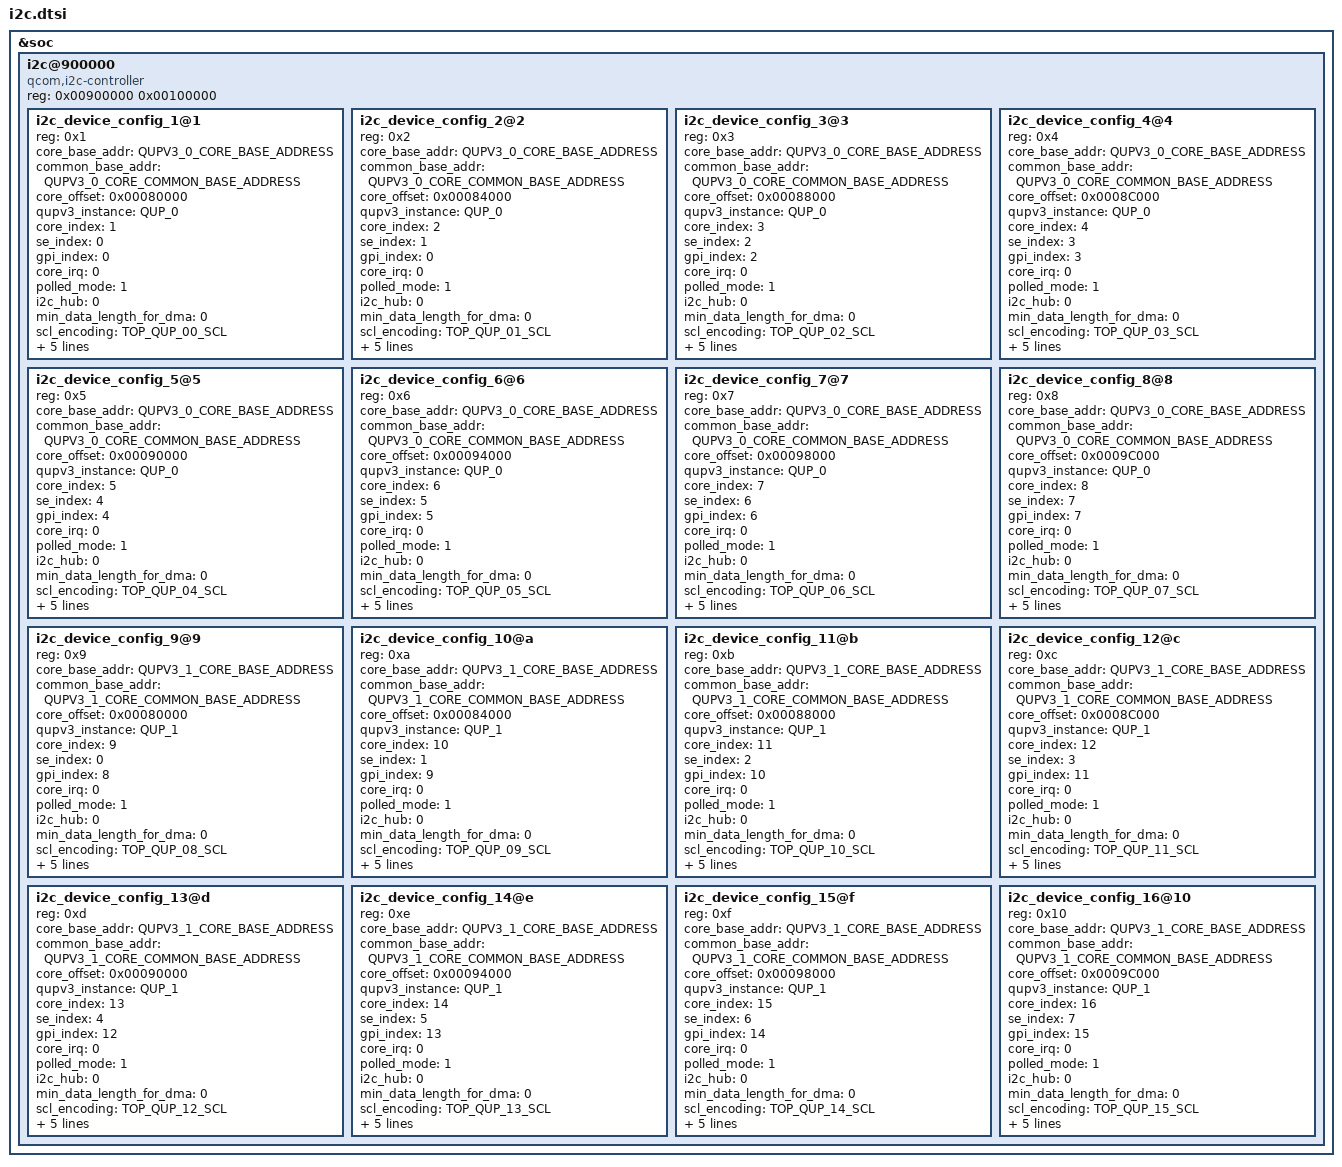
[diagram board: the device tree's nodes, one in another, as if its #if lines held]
/**

This is the settings file for I2c

Copyright (c) 2023 Qualcomm Technologies, Inc.
All Rights Reserved.
Confidential and Proprietary - Qualcomm Technologies, Inc.
*/

#include "i2c_defines.h"

&soc {
 i2c@900000{

  #address-cells = <1>;
  #size-cells = <0>;
  compatible = "qcom,i2c-controller";
  reg = <0x00900000 0x00100000>;
  
#ifdef ENABLE_QUP_00
  i2c_device_config_1@1 {
    reg = <0x1>;

    status                      = "okay";
    core_base_addr              = <QUPV3_0_CORE_BASE_ADDRESS>;
    common_base_addr            = <QUPV3_0_CORE_COMMON_BASE_ADDRESS>;
    core_offset                 = <0x00080000>;
    qupv3_instance              = /bits/ 8 <QUP_0>;
    core_index                  = /bits/ 8 <1>;
    se_index                    = /bits/ 8 <0>;
    gpi_index                   = /bits/ 8 <0>;
    core_irq                    = /bits/ 8 <0>;
    polled_mode                 = /bits/ 8 <1>;
    i2c_hub                     = /bits/ 8 <0>;
    min_data_length_for_dma     = /bits/ 8 <0>;

    scl_encoding                = <TOP_QUP_00_SCL>;
    sda_encoding                = <TOP_QUP_00_SDA>;

    tcsr_reg_offset             = <0x00000000>;
    tcsr_base_addr              = <0x01FC0000>;
    tcsr_reg_value              = <0x00000000>;

    se_clock                    = "gcc_qupv3_wrap0_s0_clk";
  };
#endif
#ifdef ENABLE_QUP_01
  i2c_device_config_2@2 {
    reg = <0x2>;

    status                      = "okay";
    core_base_addr              = <QUPV3_0_CORE_BASE_ADDRESS>;
    common_base_addr            = <QUPV3_0_CORE_COMMON_BASE_ADDRESS>;
    core_offset                 = <0x00084000>;
    qupv3_instance              = /bits/ 8 <QUP_0>;
    core_index                  = /bits/ 8 <2>;
    se_index                    = /bits/ 8 <1>;
    gpi_index                   = /bits/ 8 <0>;
    core_irq                    = /bits/ 8 <0>;
    polled_mode                 = /bits/ 8 <1>;
    i2c_hub                     = /bits/ 8 <0>;
    min_data_length_for_dma     = /bits/ 8 <0>;

    scl_encoding                = <TOP_QUP_01_SCL>;
    sda_encoding                = <TOP_QUP_01_SDA>;

    tcsr_reg_offset             = <0x00000000>;
    tcsr_base_addr              = <0x01FC0000>;
    tcsr_reg_value              = <0x00000000>;

    se_clock                    = "gcc_qupv3_wrap0_s1_clk";

  };
#endif
#ifdef ENABLE_QUP_02
  i2c_device_config_3@3{
    reg = <0x3>;

    status                      = "okay";
    core_base_addr              = <QUPV3_0_CORE_BASE_ADDRESS>;
    common_base_addr            = <QUPV3_0_CORE_COMMON_BASE_ADDRESS>;
    core_offset                 = <0x00088000>;
    qupv3_instance              = /bits/ 8 <QUP_0>;
    core_index                  = /bits/ 8 <3>;
    se_index                    = /bits/ 8 <2>;
    gpi_index                   = /bits/ 8 <2>;
    core_irq                    = /bits/ 8 <0>;
    polled_mode                 = /bits/ 8 <1>;
    i2c_hub                     = /bits/ 8 <0>;
    min_data_length_for_dma     = /bits/ 8 <0>;

    scl_encoding                = <TOP_QUP_02_SCL>;
    sda_encoding                = <TOP_QUP_02_SDA>;

    tcsr_reg_offset             = <0x00000000>;
    tcsr_base_addr              = <0x01FC0000>;
    tcsr_reg_value              = <0x00000000>;

    se_clock                    = "gcc_qupv3_wrap0_s2_clk";

  };
#endif
#ifdef ENABLE_QUP_03
  i2c_device_config_4@4 {
    reg = <0x4>;

    status                      = "okay";
    core_base_addr              = <QUPV3_0_CORE_BASE_ADDRESS>;
    common_base_addr            = <QUPV3_0_CORE_COMMON_BASE_ADDRESS>;
    core_offset                 = <0x0008C000>;
    qupv3_instance              = /bits/ 8 <QUP_0>;
    core_index                  = /bits/ 8 <4>;
    se_index                    = /bits/ 8 <3>;
    gpi_index                   = /bits/ 8 <3>;
    core_irq                    = /bits/ 8 <0>;
    polled_mode                 = /bits/ 8 <1>;
    i2c_hub                     = /bits/ 8 <0>;
    min_data_length_for_dma     = /bits/ 8 <0>;

    scl_encoding                = <TOP_QUP_03_SCL>;
    sda_encoding                = <TOP_QUP_03_SDA>;

    tcsr_reg_offset             = <0x00000000>;
    tcsr_base_addr              = <0x01FC0000>;
    tcsr_reg_value              = <0x00000000>;


    se_clock                    = "gcc_qupv3_wrap0_s3_clk";

  };
#endif
#ifdef ENABLE_QUP_04
  i2c_device_config_5@5 {
    reg = <0x5>;

    status                      = "okay";
    core_base_addr              = <QUPV3_0_CORE_BASE_ADDRESS>;
    common_base_addr            = <QUPV3_0_CORE_COMMON_BASE_ADDRESS>;
    core_offset                 = <0x00090000>;
    qupv3_instance              = /bits/ 8 <QUP_0>;
    core_index                  = /bits/ 8 <5>;
    se_index                    = /bits/ 8 <4>;
    gpi_index                   = /bits/ 8 <4>;
    core_irq                    = /bits/ 8 <0>;
    polled_mode                 = /bits/ 8 <1>;
    i2c_hub                     = /bits/ 8 <0>;
    min_data_length_for_dma     = /bits/ 8 <0>;

    scl_encoding                = <TOP_QUP_04_SCL>;
    sda_encoding                = <TOP_QUP_04_SDA>;

    tcsr_reg_offset             = <0x00000000>;
    tcsr_base_addr              = <0x01FC0000>;
    tcsr_reg_value              = <0x00000000>;

    se_clock                    = "gcc_qupv3_wrap0_s4_clk";

  };
#endif
#ifdef ENABLE_QUP_05
  i2c_device_config_6@6 {
    reg = <0x6>;

    status                      = "okay";
    core_base_addr              = <QUPV3_0_CORE_BASE_ADDRESS>;
    common_base_addr            = <QUPV3_0_CORE_COMMON_BASE_ADDRESS>;
    core_offset                 = <0x00094000>;
    qupv3_instance              = /bits/ 8 <QUP_0>;
    core_index                  = /bits/ 8 <6>;
    se_index                    = /bits/ 8 <5>;
    gpi_index                   = /bits/ 8 <5>;
    core_irq                    = /bits/ 8 <0>;
    polled_mode                 = /bits/ 8 <1>;
    i2c_hub                     = /bits/ 8 <0>;
    min_data_length_for_dma     = /bits/ 8 <0>;

    scl_encoding                = <TOP_QUP_05_SCL>;
    sda_encoding                = <TOP_QUP_05_SDA>;

    tcsr_reg_offset             = <0x00000000>;
    tcsr_base_addr              = <0x01FC0000>;
    tcsr_reg_value              = <0x00000000>;

    se_clock                    = "gcc_qupv3_wrap0_s5_clk";

  };
#endif
#ifdef ENABLE_QUP_06
  i2c_device_config_7@7 {
    reg = <0x7>;

    status                      = "okay";
    core_base_addr              = <QUPV3_0_CORE_BASE_ADDRESS>;
    common_base_addr            = <QUPV3_0_CORE_COMMON_BASE_ADDRESS>;
    core_offset                 = <0x00098000>;
    qupv3_instance              = /bits/ 8 <QUP_0>;
    core_index                  = /bits/ 8 <7>;
    se_index                    = /bits/ 8 <6>;
    gpi_index                   = /bits/ 8 <6>;
    core_irq                    = /bits/ 8 <0>;
    polled_mode                 = /bits/ 8 <1>;
    i2c_hub                     = /bits/ 8 <0>;
    min_data_length_for_dma     = /bits/ 8 <0>;

    scl_encoding                = <TOP_QUP_06_SCL>;
    sda_encoding                = <TOP_QUP_06_SDA>;

    tcsr_reg_offset             = <0x00000000>;
    tcsr_base_addr              = <0x01FC0000>;
    tcsr_reg_value              = <0x00000000>;

    se_clock                    = "gcc_qupv3_wrap0_s6_clk";
  };
#endif
#ifdef ENABLE_QUP_07
  i2c_device_config_8@8 {
    reg = <0x8>;

    status                      = "okay";
    core_base_addr              = <QUPV3_0_CORE_BASE_ADDRESS>;
    common_base_addr            = <QUPV3_0_CORE_COMMON_BASE_ADDRESS>;
    core_offset                 = <0x0009C000>;
    qupv3_instance              = /bits/ 8 <QUP_0>;
    core_index                  = /bits/ 8 <8>;
    se_index                    = /bits/ 8 <7>;
    gpi_index                   = /bits/ 8 <7>;
    core_irq                    = /bits/ 8 <0>;
    polled_mode                 = /bits/ 8 <1>;
    i2c_hub                     = /bits/ 8 <0>;
    min_data_length_for_dma     = /bits/ 8 <0>;

    scl_encoding                = <TOP_QUP_07_SCL>;
    sda_encoding                = <TOP_QUP_07_SDA>;

    tcsr_reg_offset             = <0x00000000>;
    tcsr_base_addr              = <0x01FC0000>;
    tcsr_reg_value              = <0x00000000>;

    se_clock                    = "gcc_qupv3_wrap0_s7_clk";

  };
#endif
#ifdef ENABLE_QUP_08
  i2c_device_config_9@9 {
    reg = <0x9>;

    status                      = "okay";
    core_base_addr              = <QUPV3_1_CORE_BASE_ADDRESS>;
    common_base_addr            = <QUPV3_1_CORE_COMMON_BASE_ADDRESS>;
    core_offset                 = <0x00080000>;
    qupv3_instance              = /bits/ 8 <QUP_1>;
    core_index                  = /bits/ 8 <9>;
    se_index                    = /bits/ 8 <0>;
    gpi_index                   = /bits/ 8 <8>;
    core_irq                    = /bits/ 8 <0>;
    polled_mode                 = /bits/ 8 <1>;
    i2c_hub                     = /bits/ 8 <0>;
    min_data_length_for_dma     = /bits/ 8 <0>;

    scl_encoding                = <TOP_QUP_08_SCL>;
    sda_encoding                = <TOP_QUP_08_SDA>;

    tcsr_reg_offset             = <0x00000000>;
    tcsr_base_addr              = <0x01FC0000>;
    tcsr_reg_value              = <0x00000000>;

    se_clock                    = "gcc_qupv3_wrap1_s0_clk";

  };
#endif
#ifdef ENABLE_QUP_09
  i2c_device_config_10@a {
    reg = <0xa>;

    status                      = "okay";
    core_base_addr              = <QUPV3_1_CORE_BASE_ADDRESS>;
    common_base_addr            = <QUPV3_1_CORE_COMMON_BASE_ADDRESS>;
    core_offset                 = <0x00084000>;
    qupv3_instance              = /bits/ 8 <QUP_1>;
    core_index                  = /bits/ 8 <10>;
    se_index                    = /bits/ 8 <1>;
    gpi_index                   = /bits/ 8 <9>;
    core_irq                    = /bits/ 8 <0>;
    polled_mode                 = /bits/ 8 <1>;
    i2c_hub                     = /bits/ 8 <0>;
    min_data_length_for_dma     = /bits/ 8 <0>;

    scl_encoding                = <TOP_QUP_09_SCL>;
    sda_encoding                = <TOP_QUP_09_SDA>;

    tcsr_reg_offset             = <0x00000000>;
    tcsr_base_addr              = <0x01FC0000>;
    tcsr_reg_value              = <0x00000000>;

    se_clock                    = "gcc_qupv3_wrap1_s1_clk";
	
  };
#endif
#ifdef ENABLE_QUP_10
  i2c_device_config_11@b {
    reg = <0xb>;

    status                      = "okay";
    core_base_addr              = <QUPV3_1_CORE_BASE_ADDRESS>;
    common_base_addr            = <QUPV3_1_CORE_COMMON_BASE_ADDRESS>;
    core_offset                 = <0x00088000>;
    qupv3_instance              = /bits/ 8 <QUP_1>;
    core_index                  = /bits/ 8 <11>;
    se_index                    = /bits/ 8 <2>;
    gpi_index                   = /bits/ 8 <10>;
    core_irq                    = /bits/ 8 <0>;
    polled_mode                 = /bits/ 8 <1>;
    i2c_hub                     = /bits/ 8 <0>;
    min_data_length_for_dma     = /bits/ 8 <0>;

    scl_encoding                = <TOP_QUP_10_SCL>;
    sda_encoding                = <TOP_QUP_10_SDA>;

    tcsr_reg_offset             = <0x00000000>;
    tcsr_base_addr              = <0x01FC0000>;
    tcsr_reg_value              = <0x00000000>;

    se_clock                    = "gcc_qupv3_wrap1_s2_clk";


  };
#endif
#ifdef ENABLE_QUP_11
  i2c_device_config_12@c {
    reg = <0xc>;

    status                      = "okay";
    core_base_addr              = <QUPV3_1_CORE_BASE_ADDRESS>;
    common_base_addr            = <QUPV3_1_CORE_COMMON_BASE_ADDRESS>;
    core_offset                 = <0x0008C000>;
    qupv3_instance              = /bits/ 8 <QUP_1>;
    core_index                  = /bits/ 8 <12>;
    se_index                    = /bits/ 8 <3>;
    gpi_index                   = /bits/ 8 <11>;
    core_irq                    = /bits/ 8 <0>;
    polled_mode                 = /bits/ 8 <1>;
    i2c_hub                     = /bits/ 8 <0>;
    min_data_length_for_dma     = /bits/ 8 <0>;

    scl_encoding                = <TOP_QUP_11_SCL>;
    sda_encoding                = <TOP_QUP_11_SDA>;

    tcsr_reg_offset             = <0x00000000>;
    tcsr_base_addr              = <0x01FC0000>;
    tcsr_reg_value              = <0x00000000>;

    se_clock                    = "gcc_qupv3_wrap1_s3_clk";

  };
#endif
#ifdef ENABLE_QUP_12
  i2c_device_config_13@d {
    reg = <0xd>;

    status                      = "okay";
    core_base_addr              = <QUPV3_1_CORE_BASE_ADDRESS>;
    common_base_addr            = <QUPV3_1_CORE_COMMON_BASE_ADDRESS>;
    core_offset                 = <0x00090000>;
    qupv3_instance              = /bits/ 8 <QUP_1>;
    core_index                  = /bits/ 8 <13>;
    se_index                    = /bits/ 8 <4>;
    gpi_index                   = /bits/ 8 <12>;
    core_irq                    = /bits/ 8 <0>;
    polled_mode                 = /bits/ 8 <1>;
    i2c_hub                     = /bits/ 8 <0>;
    min_data_length_for_dma     = /bits/ 8 <0>;

    scl_encoding                = <TOP_QUP_12_SCL>;
    sda_encoding                = <TOP_QUP_12_SDA>;

    tcsr_reg_offset             = <0x00000000>;
    tcsr_base_addr              = <0x01FC0000>;
    tcsr_reg_value              = <0x00000000>;

    se_clock                    = "gcc_qupv3_wrap1_s4_clk";

  };
#endif
#ifdef ENABLE_QUP_13
  i2c_device_config_14@e {
    reg = <0xe>;

    status                      = "okay";
    core_base_addr              = <QUPV3_1_CORE_BASE_ADDRESS>;
    common_base_addr            = <QUPV3_1_CORE_COMMON_BASE_ADDRESS>;
    core_offset                 = <0x00094000>;
    qupv3_instance              = /bits/ 8 <QUP_1>;
    core_index                  = /bits/ 8 <14>;
    se_index                    = /bits/ 8 <5>;
    gpi_index                   = /bits/ 8 <13>;
    core_irq                    = /bits/ 8 <0>;
    polled_mode                 = /bits/ 8 <1>;
    i2c_hub                     = /bits/ 8 <0>;
    min_data_length_for_dma     = /bits/ 8 <0>;

    scl_encoding                = <TOP_QUP_13_SCL>;
    sda_encoding                = <TOP_QUP_13_SDA>;

    tcsr_reg_offset             = <0x00000000>;
    tcsr_base_addr              = <0x01FC0000>;
    tcsr_reg_value              = <0x00000000>;


    se_clock                    = "gcc_qupv3_wrap1_s5_clk";

  };
#endif
#ifdef ENABLE_QUP_14
  i2c_device_config_15@f {
    reg = <0xf>;

    status                      = "okay";
    core_base_addr              = <QUPV3_1_CORE_BASE_ADDRESS>;
    common_base_addr            = <QUPV3_1_CORE_COMMON_BASE_ADDRESS>;
    core_offset                 = <0x00098000>;
    qupv3_instance              = /bits/ 8 <QUP_1>;
    core_index                  = /bits/ 8 <15>;
    se_index                    = /bits/ 8 <6>;
    gpi_index                   = /bits/ 8 <14>;
    core_irq                    = /bits/ 8 <0>;
    polled_mode                 = /bits/ 8 <1>;
    i2c_hub                     = /bits/ 8 <0>;
    min_data_length_for_dma     = /bits/ 8 <0>;

    scl_encoding                = <TOP_QUP_14_SCL>;
    sda_encoding                = <TOP_QUP_14_SDA>;

    tcsr_reg_offset             = <0x00000000>;
    tcsr_base_addr              = <0x01FC0000>;
    tcsr_reg_value              = <0x00000000>;

    se_clock                    = "gcc_qupv3_wrap1_s6_clk";

  };
#endif
#ifdef ENABLE_QUP_15
  i2c_device_config_16@10 {
    reg = <0x10>;

    status                      = "okay";
    core_base_addr              = <QUPV3_1_CORE_BASE_ADDRESS>;
    common_base_addr            = <QUPV3_1_CORE_COMMON_BASE_ADDRESS>;
    core_offset                 = <0x0009C000>;
    qupv3_instance              = /bits/ 8 <QUP_1>;
    core_index                  = /bits/ 8 <16>;
    se_index                    = /bits/ 8 <7>;
    gpi_index                   = /bits/ 8 <15>;
    core_irq                    = /bits/ 8 <0>;
    polled_mode                 = /bits/ 8 <1>;
    i2c_hub                     = /bits/ 8 <0>;
    min_data_length_for_dma     = /bits/ 8 <0>;

    scl_encoding                = <TOP_QUP_15_SCL>;
    sda_encoding                = <TOP_QUP_15_SDA>;

    tcsr_reg_offset             = <0x00000000>;
    tcsr_base_addr              = <0x01FC0000>;
    tcsr_reg_value              = <0x00000000>;
    se_clock                    = "gcc_qupv3_wrap1_s7_clk";

  };
#endif
 };
};
